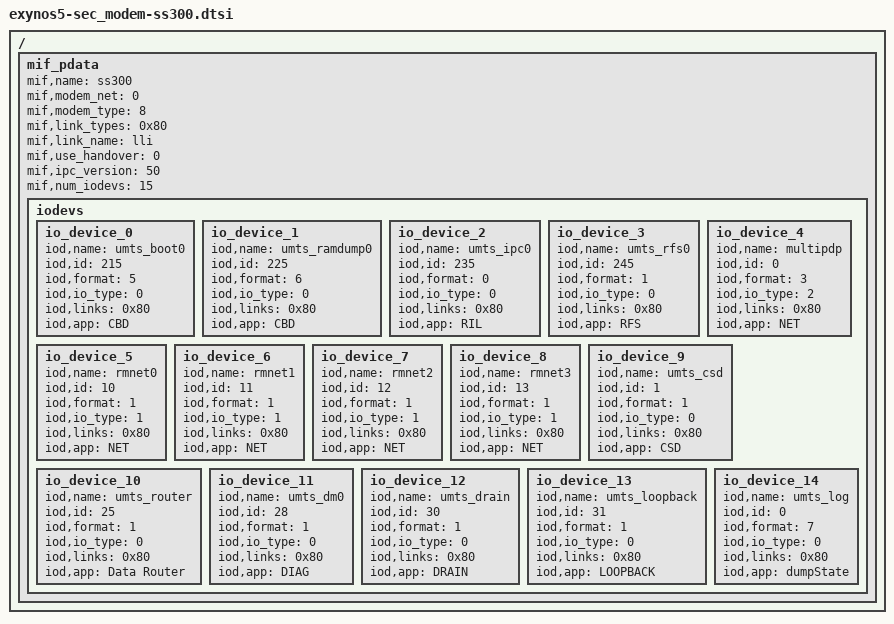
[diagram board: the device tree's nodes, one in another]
/*
 * SAMSUNG universal5422 board device tree source
 *
 * Copyright (c) 2013 Samsung Electronics Co., Ltd.
 *             http://www.samsung.com
 *
 * This program is free software; you can redistribute it and/or modify
 * it under the terms of the GNU General Public License version 2 as
 * published by the Free Software Foundation.
*/

/* modem_interface_driver: UMTS modem, 2G/3G/4G, Samsung Electronics Shannon300 (SS300) */

/ {
	mif_pdata {
		mif,name = "ss300";
		mif,modem_net = <0>;
		mif,modem_type = <8>;
		mif,link_types = <0x80>;
		mif,link_name = "lli";
		mif,use_handover = <0>;
		mif,ipc_version = <50>;

		mif,num_iodevs = <15>;
		iodevs {
			io_device_0 {
				iod,name = "umts_boot0";
				iod,id = <215>;
				iod,format = <5>;
				iod,io_type = <0>;
				iod,links = <0x80>;
				iod,app = "CBD";
			};
			io_device_1 {
				iod,name = "umts_ramdump0";
				iod,id = <225>;
				iod,format = <6>;
				iod,io_type = <0>;
				iod,links = <0x80>;
				iod,app = "CBD";
			};
			io_device_2 {
				iod,name = "umts_ipc0";
				iod,id = <235>;
				iod,format = <0>;
				iod,io_type = <0>;
				iod,links = <0x80>;
				iod,app = "RIL";
			};
			io_device_3 {
				iod,name = "umts_rfs0";
				iod,id = <245>;
				iod,format = <1>;
				iod,io_type = <0>;
				iod,links = <0x80>;
				iod,app = "RFS";
			};
			io_device_4 {
				iod,name = "multipdp";
				iod,id = <0>;
				iod,format = <3>;
				iod,io_type = <2>;
				iod,links = <0x80>;
				iod,app = "NET";
			};
			io_device_5 {
				iod,name = "rmnet0";
				iod,id = <10>;
				iod,format = <1>;
				iod,io_type = <1>;
				iod,links = <0x80>;
				iod,app = "NET";
			};
			io_device_6 {
				iod,name = "rmnet1";
				iod,id = <11>;
				iod,format = <1>;
				iod,io_type = <1>;
				iod,links = <0x80>;
				iod,app = "NET";
			};
			io_device_7 {
				iod,name = "rmnet2";
				iod,id = <12>;
				iod,format = <1>;
				iod,io_type = <1>;
				iod,links = <0x80>;
				iod,app = "NET";
			};
			io_device_8 {
				iod,name = "rmnet3";
				iod,id = <13>;
				iod,format = <1>;
				iod,io_type = <1>;
				iod,links = <0x80>;
				iod,app = "NET";
			};
			io_device_9 {
				iod,name = "umts_csd";
				iod,id = <1>;
				iod,format = <1>;
				iod,io_type = <0>;
				iod,links = <0x80>;
				iod,app = "CSD";
			};
			io_device_10 {
				iod,name = "umts_router";
				iod,id = <25>;
				iod,format = <1>;
				iod,io_type = <0>;
				iod,links = <0x80>;
				iod,app = "Data Router";
			};
			io_device_11 {
				iod,name = "umts_dm0";
				iod,id = <28>;
				iod,format = <1>;
				iod,io_type = <0>;
				iod,links = <0x80>;
				iod,app = "DIAG";
			};
			io_device_12 {
				iod,name = "umts_drain";
				iod,id = <30>;
				iod,format = <1>;
				iod,io_type = <0>;
				iod,links = <0x80>;
				iod,app = "DRAIN";
			};
			io_device_13 {
				iod,name = "umts_loopback";
				iod,id = <31>;
				iod,format = <1>;
				iod,io_type = <0>;
				iod,links = <0x80>;
				iod,app = "LOOPBACK";
			};
			io_device_14 {
				iod,name = "umts_log";
				iod,id = <0>;
				iod,format = <7>;
				iod,io_type = <0>;
				iod,links = <0x80>;
				iod,app = "dumpState";
			};
		}; /* end of iodevs */
	}; /* end of mif_pdata */
};
